# MKL27Z644 register map
Vendor: Freescale Semiconductor, Inc.; Series: Kinetis_L; File version: 1.6
CPU: CM0PLUS r0p0, little endian, no MPU, no FPU, VTOR, 2 interrupt priority bits
Registers are 32-bit, read-write, reset 0x0 unless marked. A register's access mark holds for its fields unless they carry their own. Offsets are from the block's base; [hi:lo] are bit positions; {n}, {i} and the like mark numbered series.

## USB0 — Universal Serial Bus, OTG Capable Controller
Base 0x40072000; register names take the prefix USB0_
0x00 PERID 8-bit ro reset 0x4 — Peripheral ID register
  [5:0] ID — Peripheral Identification
0x04 IDCOMP 8-bit ro reset 0xFB — Peripheral ID Complement register
  [5:0] NID — Ones' complement of PERID[ID]. bits.
0x08 REV 8-bit ro reset 0x33 — Peripheral Revision register
  [7:0] REV — Revision
0x0C ADDINFO 8-bit ro reset 0x1 — Peripheral Additional Info register
  [0] IEHOST — This bit is set if host mode is enabled.
0x1C OTGCTL 8-bit — OTG Control register
  [7] DPHIGH — D+ Data Line pullup resistor enable
    0=D+ pullup resistor is not enabled; 1=D+ pullup resistor is enabled
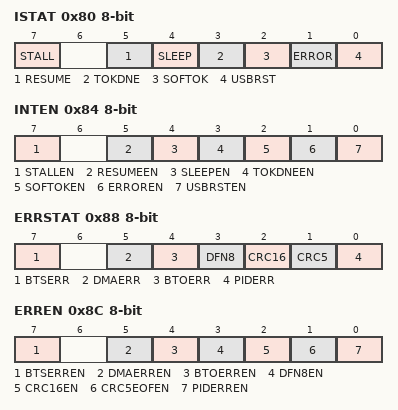
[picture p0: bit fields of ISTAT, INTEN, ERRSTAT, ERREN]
0x80 ISTAT 8-bit — Interrupt Status register
  [7] STALL — Stall Interrupt
  [5] RESUME — This bit is set when a K-state is observed on the DP/DM signals for 2
  [4] SLEEP — This bit is set when the USB Module detects a constant idle on the USB bus for 3 ms
  [3] TOKDNE — This bit is set when the current token being processed has completed
  [2] SOFTOK — This bit is set when the USB Module receives a Start Of Frame (SOF) token.
  [1] ERROR — This bit is set when any of the error conditions within Error Interrupt Status (ERRSTAT) register occur
  [0] USBRST — This bit is set when the USB Module has decoded a valid USB reset
0x84 INTEN 8-bit — Interrupt Enable register
  [7] STALLEN — STALL Interrupt Enable
    0=Diasbles the STALL interrupt; 1=Enables the STALL interrupt
  [5] RESUMEEN — RESUME Interrupt Enable
    0=Disables the RESUME interrupt; 1=Enables the RESUME interrupt
  [4] SLEEPEN — SLEEP Interrupt Enable
    0=Disables the SLEEP interrupt; 1=Enables the SLEEP interrupt
  [3] TOKDNEEN — TOKDNE Interrupt Enable
    0=Disables the TOKDNE interrupt; 1=Enables the TOKDNE interrupt
  [2] SOFTOKEN — SOFTOK Interrupt Enable
    0=Disbles the SOFTOK interrupt; 1=Enables the SOFTOK interrupt
  [1] ERROREN — ERROR Interrupt Enable
    0=Disables the ERROR interrupt; 1=Enables the ERROR interrupt
  [0] USBRSTEN — USBRST Interrupt Enable
    0=Disables the USBRST interrupt; 1=Enables the USBRST interrupt
0x88 ERRSTAT 8-bit — Error Interrupt Status register
  [7] BTSERR — This bit is set when a bit stuff error is detected
  [5] DMAERR — This bit is set if the USB Module has requested a DMA access to read a new BDT but has not been given the bus before it needs to receive or transmit data
  [4] BTOERR — This bit is set when a bus turnaround timeout error occurs
  [3] DFN8 — This bit is set if the data field received was not 8 bits in length
  [2] CRC16 — This bit is set when a data packet is rejected due to a CRC16 error.
  [1] CRC5 — This error interrupt has two functions
  [0] PIDERR — This bit is set when the PID check field fails.
0x8C ERREN 8-bit — Error Interrupt Enable register
  [7] BTSERREN — BTSERR Interrupt Enable
    0=Disables the BTSERR interrupt; 1=Enables the BTSERR interrupt
  [5] DMAERREN — DMAERR Interrupt Enable
    0=Disables the DMAERR interrupt; 1=Enables the DMAERR interrupt
  [4] BTOERREN — BTOERR Interrupt Enable
    0=Disables the BTOERR interrupt; 1=Enables the BTOERR interrupt
  [3] DFN8EN — DFN8 Interrupt Enable
    0=Disables the DFN8 interrupt; 1=Enables the DFN8 interrupt
  [2] CRC16EN — CRC16 Interrupt Enable
    0=Disables the CRC16 interrupt; 1=Enables the CRC16 interrupt
  [1] CRC5EOFEN — CRC5/EOF Interrupt Enable
    0=Disables the CRC5/EOF interrupt; 1=Enables the CRC5/EOF interrupt
  [0] PIDERREN — PIDERR Interrupt Enable
    0=Disables the PIDERR interrupt; 1=Enters the PIDERR interrupt
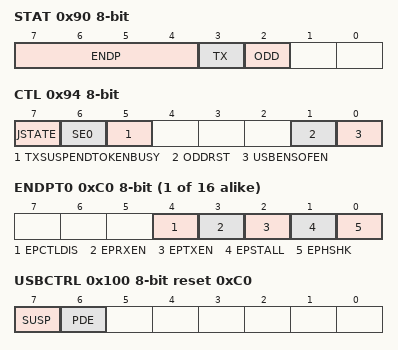
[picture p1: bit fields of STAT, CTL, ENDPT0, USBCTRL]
0x90 STAT 8-bit ro — Status register
  [7:4] ENDP — This four-bit field encodes the endpoint address that received or transmitted the previous token
  [3] TX — Transmit Indicator
    0=The most recent transaction was a receive operation; 1=The most recent transaction was a transmit operation
  [2] ODD — This bit is set if the last buffer descriptor updated was in the odd bank of the BDT.
0x94 CTL 8-bit — Control register
  [7] JSTATE — Live USB differential receiver JSTATE signal
  [6] SE0 — Live USB Single Ended Zero signal
  [5] TXSUSPENDTOKENBUSY — In Target mode, TXD_SUSPEND is set when the SIE has disabled packet transmission and reception
  [1] ODDRST — Setting this bit to 1 resets all the BDT ODD ping/pong fields to 0, which then specifies the EVEN BDT bank
  [0] USBENSOFEN — USB Enable
    0=Disables the USB Module; 1=Enables the USB Module
0x98 ADDR 8-bit — Address register
  [6:0] ADDR — USB Address
0x9C BDTPAGE1 8-bit — BDT Page register 1
  [7:1] BDTBA — Provides address bits 15 through 9 of the BDT base address.
0xA0 FRMNUML 8-bit — Frame Number register Low
  [7:0] FRM — This 8-bit field and the 3-bit field in the Frame Number Register High are used to compute the address where the current Buffer Descriptor Table (BDT) resides in system memory
0xA4 FRMNUMH 8-bit — Frame Number register High
  [2:0] FRM — This 3-bit field and the 8-bit field in the Frame Number Register Low are used to compute the address where the current Buffer Descriptor Table (BDT) resides in system memory
0xB0 BDTPAGE2 8-bit — BDT Page Register 2
  [7:0] BDTBA — Provides address bits 23 through 16 of the BDT base address that defines the location of Buffer Descriptor Table resides in system memory
0xB4 BDTPAGE3 8-bit — BDT Page Register 3
  [7:0] BDTBA — Provides address bits 31 through 24 of the BDT base address that defines the location of Buffer Descriptor Table resides in system memory
{0xC0+4i} ENDPT{i} (i=0..15) 8-bit — Endpoint Control register
  [4] EPCTLDIS — This bit, when set, disables control (SETUP) transfers
  [3] EPRXEN — This bit, when set, enables the endpoint for RX transfers. See #aal353jj
  [2] EPTXEN — This bit, when set, enables the endpoint for TX transfers. See #aal353jj
  [1] EPSTALL — When set this bit indicates that the endpoint is called
  [0] EPHSHK — When set this bit enables an endpoint to perform handshaking during a transaction to this endpoint
0x100 USBCTRL 8-bit reset 0xC0 — USB Control register
  [7] SUSP — Places the USB transceiver into the suspend state.
    0=USB transceiver is not in suspend state; 1=USB transceiver is in suspend state
  [6] PDE — Enables the weak pulldowns on the USB transceiver.
    0=Weak pulldowns are disabled on D+ and D-; 1=Weak pulldowns are enabled on D+ and D-
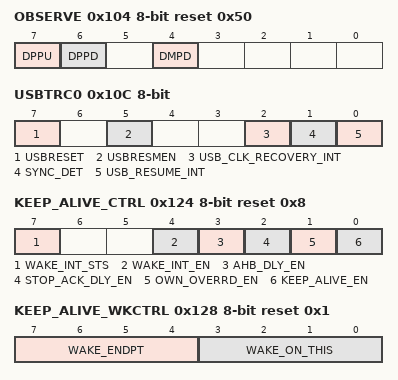
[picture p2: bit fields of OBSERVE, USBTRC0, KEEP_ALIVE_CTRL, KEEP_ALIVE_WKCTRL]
0x104 OBSERVE 8-bit ro reset 0x50 — USB OTG Observe register
  [7] DPPU — Provides observability of the D+ Pullup signal output from USB .
    0=D+ pullup disabled; 1=D+ pullup enabled
  [6] DPPD — Provides observability of the D+ Pulldown signal output from USB.
    0=D+ pulldown disabled; 1=D+ pulldown enabled
  [4] DMPD — Provides observability of the D- Pulldown signal output from USB.
    0=D- pulldown disabled; 1=D- pulldown enabled
0x108 CONTROL 8-bit — USB OTG Control register
  [4] DPPULLUPNONOTG — Provides control of the DP Pullup in USB, if USB is configured in non-OTG device mode.
    0=DP Pullup in non-OTG device mode is not enabled; 1=DP Pullup in non-OTG device mode is enabled
0x10C USBTRC0 8-bit — USB Transceiver Control register 0
  [7] USBRESET wo
    0=Normal USB module operation; 1=Returns the USB module to its reset state
  [5] USBRESMEN — Asynchronous Resume Interrupt Enable
    0=USB asynchronous wakeup from suspend mode disabled; 1=USB asynchronous wakeup from suspend mode enabled. The asynchronous resume interrupt differs from the synchronous resume interrupt in that it asynchronously detects K-state using the unfiltered state of the D+ and D- pins. This interrupt should only be enabled when the Transceiver is suspended.
  [2] USB_CLK_RECOVERY_INT ro — Combined USB Clock Recovery interrupt status
  [1] SYNC_DET ro — Synchronous USB Interrupt Detect
    0=Synchronous interrupt has not been detected; 1=Synchronous interrupt has been detected
  [0] USB_RESUME_INT ro — USB Asynchronous Interrupt
    0=No interrupt was generated; 1=Interrupt was generated because of the USB asynchronous interrupt
0x114 USBFRMADJUST 8-bit — Frame Adjust Register
  [7:0] ADJ — Frame Adjustment
0x124 KEEP_ALIVE_CTRL 8-bit reset 0x8 — Keep Alive mode control
  [7] WAKE_INT_STS ro — Wakeup Interrupt Status.
  [4] WAKE_INT_EN — Wakeup Interrupt Enable.
  [3] AHB_DLY_EN — Must be set to 1 to delay the first USB AHB bus transfer until after the USB has exited KEEP_ALIVE mode
    0=Do not delay the USB AHB transfer if the USB AHB transfer occurs while exiting KEEP_ALIVE mode; 1=Delay the USB AHB transfer until the clock is recovered, if the USB AHB transfer occurs while exiting KEEP_ALIVE mode
  [2] STOP_ACK_DLY_EN — When set to 1, will respond the ipg_stop when usb core state is idle and no AHB transfer; when set to 0, will respond the ipg_stop when no AHB transfer
    0=Enter KEEP_ALIVE mode until the USB core is idle and there is no USB AHB transfer; 1=Enter KEEP_ALIVE mode immediately when there is no USB AHB transfer
  [1] OWN_OVERRD_EN — When set to 1, during KEEP_ALIVE mode, if received token is not SETUP, the OWN bit of current BD will be forced to 0, so usb core will response with NAK
  [0] KEEP_ALIVE_EN — Global enable for USB_KEEP_ALIVE mode
0x128 KEEP_ALIVE_WKCTRL 8-bit reset 0x1 — Keep Alive mode wakeup control
  [7:4] WAKE_ENDPT ro — Indicates which endpoint causes the wakeup interrupt. Reset to 0, software read only.
  [3:0] WAKE_ON_THIS — Software configure it to which token can wakeup usb during KEEP_ALIVE mode
    1=Wake up on receiving OUT/SETUP token packet; 13=Wake up on receiving SETUP token packet.All other values are reserved
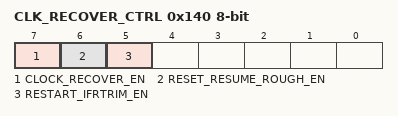
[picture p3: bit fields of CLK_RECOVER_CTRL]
0x140 CLK_RECOVER_CTRL 8-bit — USB Clock recovery control
  [7] CLOCK_RECOVER_EN — Crystal-less USB enable
    0=Disable clock recovery block (default); 1=Enable clock recovery block
  [6] RESET_RESUME_ROUGH_EN — Reset/resume to rough phase enable
    0=Always works in tracking phase after the 1st time rough to track transition (default); 1=Go back to rough stage whenever bus reset or bus resume occurs
  [5] RESTART_IFRTRIM_EN — Restart from IFR trim value
    0=Trim fine adjustment always works based on the previous updated trim fine value (default); 1=Trim fine restarts from the IFR trim value whenever bus_reset/bus_resume is detected or module enable is desasserted
0x144 CLK_RECOVER_IRC_EN 8-bit reset 0x1 — IRC48M oscillator enable register
  [1] IRC_EN — IRC48M enable
    0=Disable the IRC48M module (default); 1=Enable the IRC48M module
0x154 CLK_RECOVER_INT_EN 8-bit reset 0x10 — Clock recovery combined interrupt enable
  [4] OVF_ERROR_EN — Determines whether OVF_ERROR condition signal is used in generation of USB_CLK_RECOVERY_INT.
    0=The interrupt will be masked; 1=The interrupt will be enabled (default)
0x15C CLK_RECOVER_INT_STATUS 8-bit — Clock recovery separated interrupt status
  [4] OVF_ERROR — Indicates that the USB clock recovery algorithm has detected that the frequency trim adjustment needed for the IRC48M output clock is outside the available TRIM_FINE adjustment range for the IRC48M module
    0=No interrupt is reported; 1=Unmasked interrupt has been generated

## Notices in the file
Redistribution and use in source and binary forms, with or without modification,
are permitted provided that the following conditions are met:
o Redistributions of source code must retain the above copyright notice, this list
of conditions and the following disclaimer.
o Redistributions in binary form must reproduce the above copyright notice, this
list of conditions and the following disclaimer in the documentation and/or
other materials provided with the distribution.
o Neither the name of Freescale Semiconductor, Inc. nor the names of its
contributors may be used to endorse or promote products derived from this
software without specific prior written permission.
THIS SOFTWARE IS PROVIDED BY THE COPYRIGHT HOLDERS AND CONTRIBUTORS "AS IS" AND
ANY EXPRESS OR IMPLIED WARRANTIES, INCLUDING, BUT NOT LIMITED TO, THE IMPLIED
WARRANTIES OF MERCHANTABILITY AND FITNESS FOR A PARTICULAR PURPOSE ARE
DISCLAIMED. IN NO EVENT SHALL THE COPYRIGHT HOLDER OR CONTRIBUTORS BE LIABLE FOR
ANY DIRECT, INDIRECT, INCIDENTAL, SPECIAL, EXEMPLARY, OR CONSEQUENTIAL DAMAGES
(INCLUDING, BUT NOT LIMITED TO, PROCUREMENT OF SUBSTITUTE GOODS OR SERVICES;
LOSS OF USE, DATA, OR PROFITS; OR BUSINESS INTERRUPTION) HOWEVER CAUSED AND ON
ANY THEORY OF LIABILITY, WHETHER IN CONTRACT, STRICT LIABILITY, OR TORT
(INCLUDING NEGLIGENCE OR OTHERWISE) ARISING IN ANY WAY OUT OF THE USE OF THIS
SOFTWARE, EVEN IF ADVISED OF THE POSSIBILITY OF SUCH DAMAGE.
